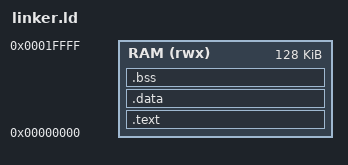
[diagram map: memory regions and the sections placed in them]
OUTPUT_ARCH(riscv)
ENTRY(_start)

MEMORY
{
    RAM (rwx) : ORIGIN = 0x00000000, LENGTH = 128K
}

SECTIONS
{
    .text :
    {
        KEEP(*(.text.start))
        *(.text .text.*)
        *(.rodata .rodata.*)
    } > RAM

    .data :
    {
        *(.data .data.*)
    } > RAM

    .bss (NOLOAD) :
    {
        __bss_start = .;
        *(.bss .bss.*)
        *(COMMON)
        __bss_end = .;
    } > RAM

    . = ALIGN(16);
    __stack_top = ORIGIN(RAM) + LENGTH(RAM);
}
